AUTOSAR XML (schema 4-2-2)
package /STELLANTIS/EPT/ASWCs
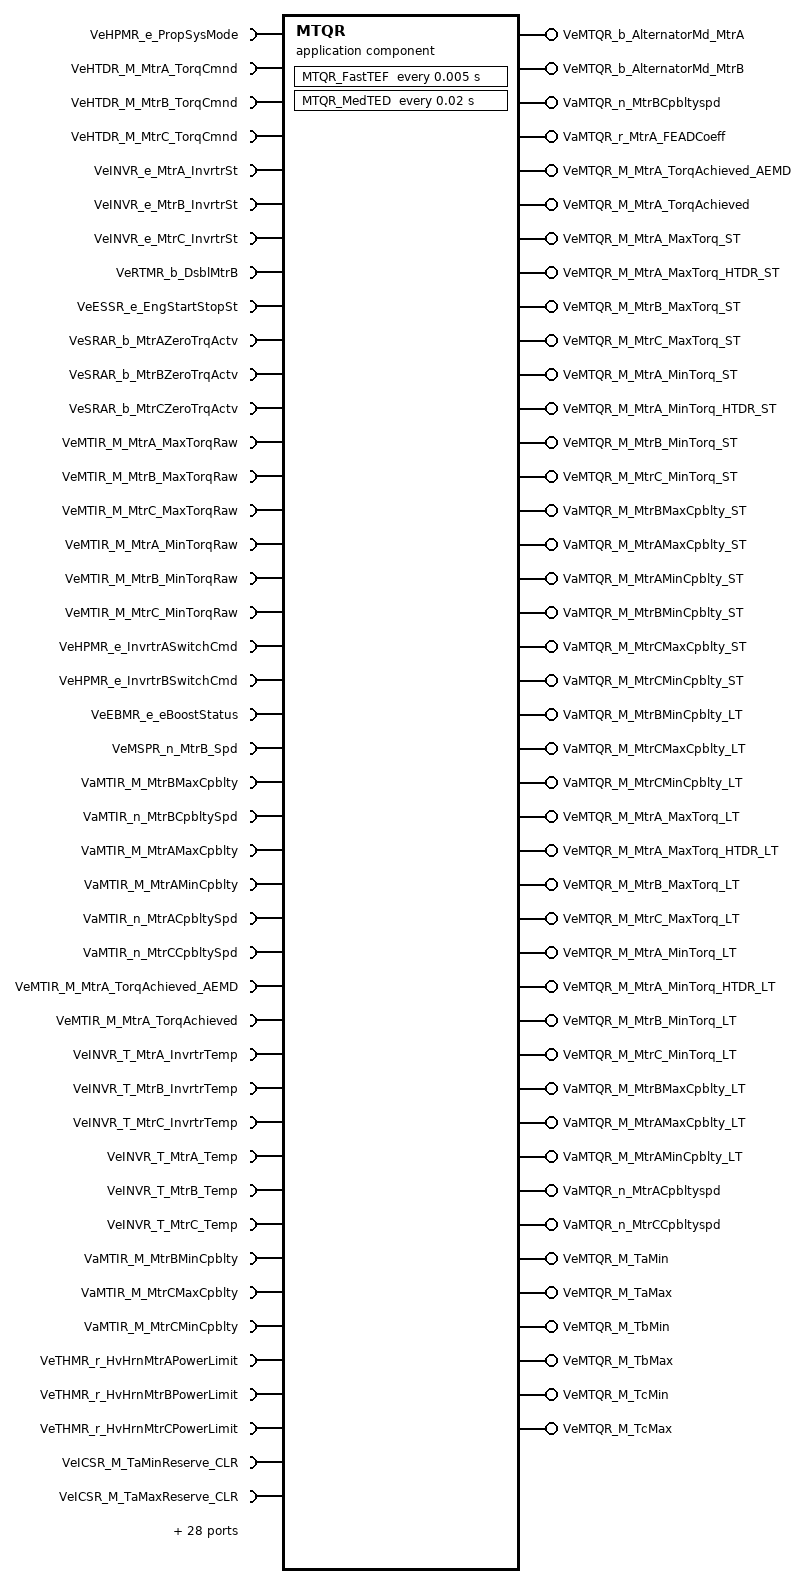
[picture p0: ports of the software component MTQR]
  application sw component type MTQR
    70 x require port:
      VeHPMR_e_PropSysMode: nonqueued-receiver-com-spec{data-element=Value, init-value=CeHPMR_e_Disabled}, required-interface=VeHPMR_e_PropSysMode
      VeHTDR_M_MtrA_TorqCmnd: nonqueued-receiver-com-spec{data-element=Value, init-value=0}, required-interface=VeHTDR_M_MtrA_TorqCmnd
      VeHTDR_M_MtrB_TorqCmnd: nonqueued-receiver-com-spec{data-element=Value, init-value=0}, required-interface=VeHTDR_M_MtrB_TorqCmnd
      VeHTDR_M_MtrC_TorqCmnd: nonqueued-receiver-com-spec{data-element=Value, init-value=0}, required-interface=VeHTDR_M_MtrC_TorqCmnd
      VeINVR_e_MtrA_InvrtrSt: nonqueued-receiver-com-spec{data-element=Value, init-value=CeINVR_e_NormalPowerStageOff}, required-interface=VeINVR_e_MtrA_InvrtrSt
      VeINVR_e_MtrB_InvrtrSt: nonqueued-receiver-com-spec{data-element=Value, init-value=CeINVR_e_NormalPowerStageOff}, required-interface=VeINVR_e_MtrB_InvrtrSt
      VeINVR_e_MtrC_InvrtrSt: nonqueued-receiver-com-spec{data-element=Value, init-value=CeINVR_e_NormalPowerStageOff}, required-interface=VeINVR_e_MtrC_InvrtrSt
      VeRTMR_b_DsblMtrB: nonqueued-receiver-com-spec{data-element=Value, init-value=0}, required-interface=VeRTMR_b_DsblMtrB
      VeESSR_e_EngStartStopSt: nonqueued-receiver-com-spec{data-element=Value, init-value=CeESSR_e_EngOff}, required-interface=VeESSR_e_EngStartStopSt
      VeSRAR_b_MtrAZeroTrqActv: nonqueued-receiver-com-spec{data-element=Value, init-value=0}, required-interface=VeSRAR_b_MtrAZeroTrqActv
      VeSRAR_b_MtrBZeroTrqActv: nonqueued-receiver-com-spec{data-element=Value, init-value=0}, required-interface=VeSRAR_b_MtrBZeroTrqActv
      VeSRAR_b_MtrCZeroTrqActv: nonqueued-receiver-com-spec{data-element=Value, init-value=0}, required-interface=VeSRAR_b_MtrCZeroTrqActv
      VeMTIR_M_MtrA_MaxTorqRaw: nonqueued-receiver-com-spec{data-element=Value, init-value=0}, required-interface=VeMTIR_M_MtrA_MaxTorqRaw
      VeMTIR_M_MtrB_MaxTorqRaw: nonqueued-receiver-com-spec{data-element=Value, init-value=0}, required-interface=VeMTIR_M_MtrB_MaxTorqRaw
      VeMTIR_M_MtrC_MaxTorqRaw: nonqueued-receiver-com-spec{data-element=Value, init-value=0}, required-interface=VeMTIR_M_MtrC_MaxTorqRaw
      VeMTIR_M_MtrA_MinTorqRaw: nonqueued-receiver-com-spec{data-element=Value, init-value=0}, required-interface=VeMTIR_M_MtrA_MinTorqRaw
      VeMTIR_M_MtrB_MinTorqRaw: nonqueued-receiver-com-spec{data-element=Value, init-value=0}, required-interface=VeMTIR_M_MtrB_MinTorqRaw
      VeMTIR_M_MtrC_MinTorqRaw: nonqueued-receiver-com-spec{data-element=Value, init-value=0}, required-interface=VeMTIR_M_MtrC_MinTorqRaw
      VeHPMR_e_InvrtrASwitchCmd: nonqueued-receiver-com-spec{data-element=Value, init-value=CeHPMR_e_Disable}, required-interface=VeHPMR_e_InvrtrASwitchCmd
      VeHPMR_e_InvrtrBSwitchCmd: nonqueued-receiver-com-spec{data-element=Value, init-value=CeHPMR_e_Disable}, required-interface=VeHPMR_e_InvrtrBSwitchCmd
      VeEBMR_e_eBoostStatus: nonqueued-receiver-com-spec{data-element=Value, init-value=CeEBMR_e_eBoostOFF}, required-interface=VeEBMR_e_eBoostStatus
      VeMSPR_n_MtrB_Spd: nonqueued-receiver-com-spec{data-element=Value, init-value=0}, required-interface=VeMSPR_n_MtrB_Spd
      VaMTIR_M_MtrBMaxCpblty: nonqueued-receiver-com-spec{data-element=Value, init-value=16 x 0}, required-interface=VaMTIR_M_MtrBMaxCpblty
      VaMTIR_n_MtrBCpbltySpd: nonqueued-receiver-com-spec{data-element=Value, init-value=16 x 0}, required-interface=VaMTIR_n_MtrBCpbltySpd
      VaMTIR_M_MtrAMaxCpblty: nonqueued-receiver-com-spec{data-element=Value, init-value=16 x 0}, required-interface=VaMTIR_M_MtrAMaxCpblty
      VaMTIR_M_MtrAMinCpblty: nonqueued-receiver-com-spec{data-element=Value, init-value=16 x 0}, required-interface=VaMTIR_M_MtrAMinCpblty
      VaMTIR_n_MtrACpbltySpd: nonqueued-receiver-com-spec{data-element=Value, init-value=16 x 0}, required-interface=VaMTIR_n_MtrACpbltySpd
      VaMTIR_n_MtrCCpbltySpd: nonqueued-receiver-com-spec{data-element=Value, init-value=16 x 0}, required-interface=VaMTIR_n_MtrCCpbltySpd
      VeMTIR_M_MtrA_TorqAchieved_AEMD: nonqueued-receiver-com-spec{data-element=Value, init-value=0}, required-interface=VeMTIR_M_MtrA_TorqAchieved_AEMD
      VeMTIR_M_MtrA_TorqAchieved: nonqueued-receiver-com-spec{data-element=Value, init-value=0}, required-interface=VeMTIR_M_MtrA_TorqAchieved
      VeINVR_T_MtrA_InvrtrTemp: nonqueued-receiver-com-spec{data-element=Value, init-value=0}, required-interface=VeINVR_T_MtrA_InvrtrTemp
      VeINVR_T_MtrB_InvrtrTemp: nonqueued-receiver-com-spec{data-element=Value, init-value=0}, required-interface=VeINVR_T_MtrB_InvrtrTemp
      VeINVR_T_MtrC_InvrtrTemp: nonqueued-receiver-com-spec{data-element=Value, init-value=0}, required-interface=VeINVR_T_MtrC_InvrtrTemp
      VeINVR_T_MtrA_Temp: nonqueued-receiver-com-spec{data-element=Value, init-value=0}, required-interface=VeINVR_T_MtrA_Temp
      VeINVR_T_MtrB_Temp: nonqueued-receiver-com-spec{data-element=Value, init-value=0}, required-interface=VeINVR_T_MtrB_Temp
      VeINVR_T_MtrC_Temp: nonqueued-receiver-com-spec{data-element=Value, init-value=0}, required-interface=VeINVR_T_MtrC_Temp
      VaMTIR_M_MtrBMinCpblty: nonqueued-receiver-com-spec{data-element=Value, init-value=16 x 0}, required-interface=VaMTIR_M_MtrBMinCpblty
      VaMTIR_M_MtrCMaxCpblty: nonqueued-receiver-com-spec{data-element=Value, init-value=16 x 0}, required-interface=VaMTIR_M_MtrCMaxCpblty
      VaMTIR_M_MtrCMinCpblty: nonqueued-receiver-com-spec{data-element=Value, init-value=16 x 0}, required-interface=VaMTIR_M_MtrCMinCpblty
      VeTHMR_r_HvHrnMtrAPowerLimit: nonqueued-receiver-com-spec{data-element=Value, init-value=0}, required-interface=VeTHMR_r_HvHrnMtrAPowerLimit
      VeTHMR_r_HvHrnMtrBPowerLimit: nonqueued-receiver-com-spec{data-element=Value, init-value=0}, required-interface=VeTHMR_r_HvHrnMtrBPowerLimit
      VeTHMR_r_HvHrnMtrCPowerLimit: nonqueued-receiver-com-spec{data-element=Value, init-value=0}, required-interface=VeTHMR_r_HvHrnMtrCPowerLimit
      VeICSR_M_TaMinReserve_CLR: nonqueued-receiver-com-spec{data-element=Value, init-value=0}, required-interface=VeICSR_M_TaMinReserve_CLR
      VeICSR_M_TaMaxReserve_CLR: nonqueued-receiver-com-spec{data-element=Value, init-value=0}, required-interface=VeICSR_M_TaMaxReserve_CLR
      VeICSR_M_TbMinReserve_CLR: nonqueued-receiver-com-spec{data-element=Value, init-value=0}, required-interface=VeICSR_M_TbMinReserve_CLR
      VeICSR_M_TbMaxReserve_CLR: nonqueued-receiver-com-spec{data-element=Value, init-value=0}, required-interface=VeICSR_M_TbMaxReserve_CLR
      VeHADR_M_MtrA_ReserveTorqNeg: nonqueued-receiver-com-spec{data-element=Value, init-value=0}, required-interface=VeHADR_M_MtrA_ReserveTorqNeg
      VeHADR_M_MtrA_ReserveTorqPos: nonqueued-receiver-com-spec{data-element=Value, init-value=0}, required-interface=VeHADR_M_MtrA_ReserveTorqPos
      VeHADR_M_MtrB_ReserveTorqNeg: nonqueued-receiver-com-spec{data-element=Value, init-value=0}, required-interface=VeHADR_M_MtrB_ReserveTorqNeg
      VeHADR_M_MtrB_ReserveTorqPos: nonqueued-receiver-com-spec{data-element=Value, init-value=0}, required-interface=VeHADR_M_MtrB_ReserveTorqPos
      VeESSR_M_MtrA_MinTorq: nonqueued-receiver-com-spec{data-element=Value, init-value=0}, required-interface=VeESSR_M_MtrA_MinTorq
      VeESSR_M_MtrA_MaxTorq: nonqueued-receiver-com-spec{data-element=Value, init-value=0}, required-interface=VeESSR_M_MtrA_MaxTorq
      VeESSR_M_MtrB_MinTorq: nonqueued-receiver-com-spec{data-element=Value, init-value=0}, required-interface=VeESSR_M_MtrB_MinTorq
      VeESSR_M_MtrB_MaxTorq: nonqueued-receiver-com-spec{data-element=Value, init-value=0}, required-interface=VeESSR_M_MtrB_MaxTorq
      VeHADR_M_MtrC_ReserveTorqNeg: nonqueued-receiver-com-spec{data-element=Value, init-value=0}, required-interface=VeHADR_M_MtrC_ReserveTorqNeg
      VeHADR_M_MtrC_ReserveTorqPos: nonqueued-receiver-com-spec{data-element=Value, init-value=0}, required-interface=VeHADR_M_MtrC_ReserveTorqPos
      VeESSR_M_MtrC_MinTorq: nonqueued-receiver-com-spec{data-element=Value, init-value=0}, required-interface=VeESSR_M_MtrC_MinTorq
      VeESSR_M_MtrC_MaxTorq: nonqueued-receiver-com-spec{data-element=Value, init-value=0}, required-interface=VeESSR_M_MtrC_MaxTorq
      VeHSER_b_DisablNxClsdLoopCntrl: nonqueued-receiver-com-spec{data-element=Value, init-value=0}, required-interface=VeHSER_b_DisablNxClsdLoopCntrl
      VeBCPR_M_BeltTrqMinHTDR: nonqueued-receiver-com-spec{data-element=Value, init-value=0}, required-interface=VeBCPR_M_BeltTrqMinHTDR
      VeBCPR_M_BeltTrqMaxHTDR: nonqueued-receiver-com-spec{data-element=Value, init-value=0}, required-interface=VeBCPR_M_BeltTrqMaxHTDR
      VeICSR_b_Disable_Ni_Global: nonqueued-receiver-com-spec{data-element=Value, init-value=0}, required-interface=VeICSR_b_Disable_Ni_Global
      VeESSR_b_AStrtPBatBoostReq: nonqueued-receiver-com-spec{data-element=Value, init-value=0}, required-interface=VeESSR_b_AStrtPBatBoostReq
      VeSCCR_b_FrntAxlRq: nonqueued-receiver-com-spec{data-element=Value, init-value=0}, required-interface=VeSCCR_b_FrntAxlRq
      VeSCCR_b_RrAxlRq: nonqueued-receiver-com-spec{data-element=Value, init-value=0}, required-interface=VeSCCR_b_RrAxlRq
      VeDTRR_e_AxleTrqRespType: nonqueued-receiver-com-spec{data-element=Value, init-value=CePTAR_e_Inactive}, required-interface=VeDTRR_e_AxleTrqRespType
      VeINVR_b_DMPI_TempStopFlag: nonqueued-receiver-com-spec{data-element=Value, init-value=0}, required-interface=VeINVR_b_DMPI_TempStopFlag
      VeRTMR_b_DsblMtr_OITR: nonqueued-receiver-com-spec{data-element=Value, init-value=0}, required-interface=VeRTMR_b_DsblMtr_OITR
      VeRTMR_b_DsblMtrA: nonqueued-receiver-com-spec{data-element=Value, init-value=0}, required-interface=VeRTMR_b_DsblMtrA
      VeESSR_b_DisableMtrA: nonqueued-receiver-com-spec{data-element=Value, init-value=0}, required-interface=VeESSR_b_DisableMtrA
    42 x provide port:
      VeMTQR_b_AlternatorMd_MtrA: nonqueued-sender-com-spec{data-element=Value, init-value=0}, provided-interface=VeMTQR_b_AlternatorMd_MtrA
      VeMTQR_b_AlternatorMd_MtrB: nonqueued-sender-com-spec{data-element=Value, init-value=0}, provided-interface=VeMTQR_b_AlternatorMd_MtrB
      VaMTQR_n_MtrBCpbltyspd: nonqueued-sender-com-spec{data-element=Value, init-value=16 x 0}, provided-interface=VaMTQR_n_MtrBCpbltyspd
      VaMTQR_r_MtrA_FEADCoeff: nonqueued-sender-com-spec{data-element=Value, init-value=[0, 0, 0]}, provided-interface=VaMTQR_r_MtrA_FEADCoeff
      VeMTQR_M_MtrA_TorqAchieved_AEMD: nonqueued-sender-com-spec{data-element=Value, init-value=0}, provided-interface=VeMTQR_M_MtrA_TorqAchieved_AEMD
      VeMTQR_M_MtrA_TorqAchieved: nonqueued-sender-com-spec{data-element=Value, init-value=0}, provided-interface=VeMTQR_M_MtrA_TorqAchieved
      VeMTQR_M_MtrA_MaxTorq_ST: nonqueued-sender-com-spec{data-element=Value, init-value=0}, provided-interface=VeMTQR_M_MtrA_MaxTorq_ST
      VeMTQR_M_MtrA_MaxTorq_HTDR_ST: nonqueued-sender-com-spec{data-element=Value, init-value=0}, provided-interface=VeMTQR_M_MtrA_MaxTorq_HTDR_ST
      VeMTQR_M_MtrB_MaxTorq_ST: nonqueued-sender-com-spec{data-element=Value, init-value=0}, provided-interface=VeMTQR_M_MtrB_MaxTorq_ST
      VeMTQR_M_MtrC_MaxTorq_ST: nonqueued-sender-com-spec{data-element=Value, init-value=0}, provided-interface=VeMTQR_M_MtrC_MaxTorq_ST
      VeMTQR_M_MtrA_MinTorq_ST: nonqueued-sender-com-spec{data-element=Value, init-value=0}, provided-interface=VeMTQR_M_MtrA_MinTorq_ST
      VeMTQR_M_MtrA_MinTorq_HTDR_ST: nonqueued-sender-com-spec{data-element=Value, init-value=0}, provided-interface=VeMTQR_M_MtrA_MinTorq_HTDR_ST
      VeMTQR_M_MtrB_MinTorq_ST: nonqueued-sender-com-spec{data-element=Value, init-value=0}, provided-interface=VeMTQR_M_MtrB_MinTorq_ST
      VeMTQR_M_MtrC_MinTorq_ST: nonqueued-sender-com-spec{data-element=Value, init-value=0}, provided-interface=VeMTQR_M_MtrC_MinTorq_ST
      VaMTQR_M_MtrBMaxCpblty_ST: nonqueued-sender-com-spec{data-element=Value, init-value=16 x 0}, provided-interface=VaMTQR_M_MtrBMaxCpblty_ST
      VaMTQR_M_MtrAMaxCpblty_ST: nonqueued-sender-com-spec{data-element=Value, init-value=16 x 0}, provided-interface=VaMTQR_M_MtrAMaxCpblty_ST
      VaMTQR_M_MtrAMinCpblty_ST: nonqueued-sender-com-spec{data-element=Value, init-value=16 x 0}, provided-interface=VaMTQR_M_MtrAMinCpblty_ST
      VaMTQR_M_MtrBMinCpblty_ST: nonqueued-sender-com-spec{data-element=Value, init-value=16 x 0}, provided-interface=VaMTQR_M_MtrBMinCpblty_ST
      VaMTQR_M_MtrCMaxCpblty_ST: nonqueued-sender-com-spec{data-element=Value, init-value=16 x 0}, provided-interface=VaMTQR_M_MtrCMaxCpblty_ST
      VaMTQR_M_MtrCMinCpblty_ST: nonqueued-sender-com-spec{data-element=Value, init-value=16 x 0}, provided-interface=VaMTQR_M_MtrCMinCpblty_ST
      VaMTQR_M_MtrBMinCpblty_LT: nonqueued-sender-com-spec{data-element=Value, init-value=16 x 0}, provided-interface=VaMTQR_M_MtrBMinCpblty_LT
      VaMTQR_M_MtrCMaxCpblty_LT: nonqueued-sender-com-spec{data-element=Value, init-value=16 x 0}, provided-interface=VaMTQR_M_MtrCMaxCpblty_LT
      VaMTQR_M_MtrCMinCpblty_LT: nonqueued-sender-com-spec{data-element=Value, init-value=16 x 0}, provided-interface=VaMTQR_M_MtrCMinCpblty_LT
      VeMTQR_M_MtrA_MaxTorq_LT: nonqueued-sender-com-spec{data-element=Value, init-value=0}, provided-interface=VeMTQR_M_MtrA_MaxTorq_LT
      VeMTQR_M_MtrA_MaxTorq_HTDR_LT: nonqueued-sender-com-spec{data-element=Value, init-value=0}, provided-interface=VeMTQR_M_MtrA_MaxTorq_HTDR_LT
      VeMTQR_M_MtrB_MaxTorq_LT: nonqueued-sender-com-spec{data-element=Value, init-value=0}, provided-interface=VeMTQR_M_MtrB_MaxTorq_LT
      VeMTQR_M_MtrC_MaxTorq_LT: nonqueued-sender-com-spec{data-element=Value, init-value=0}, provided-interface=VeMTQR_M_MtrC_MaxTorq_LT
      VeMTQR_M_MtrA_MinTorq_LT: nonqueued-sender-com-spec{data-element=Value, init-value=0}, provided-interface=VeMTQR_M_MtrA_MinTorq_LT
      VeMTQR_M_MtrA_MinTorq_HTDR_LT: nonqueued-sender-com-spec{data-element=Value, init-value=0}, provided-interface=VeMTQR_M_MtrA_MinTorq_HTDR_LT
      VeMTQR_M_MtrB_MinTorq_LT: nonqueued-sender-com-spec{data-element=Value, init-value=0}, provided-interface=VeMTQR_M_MtrB_MinTorq_LT
      VeMTQR_M_MtrC_MinTorq_LT: nonqueued-sender-com-spec{data-element=Value, init-value=0}, provided-interface=VeMTQR_M_MtrC_MinTorq_LT
      VaMTQR_M_MtrBMaxCpblty_LT: nonqueued-sender-com-spec{data-element=Value, init-value=16 x 0}, provided-interface=VaMTQR_M_MtrBMaxCpblty_LT
      VaMTQR_M_MtrAMaxCpblty_LT: nonqueued-sender-com-spec{data-element=Value, init-value=16 x 0}, provided-interface=VaMTQR_M_MtrAMaxCpblty_LT
      VaMTQR_M_MtrAMinCpblty_LT: nonqueued-sender-com-spec{data-element=Value, init-value=16 x 0}, provided-interface=VaMTQR_M_MtrAMinCpblty_LT
      VaMTQR_n_MtrACpbltyspd: nonqueued-sender-com-spec{data-element=Value, init-value=16 x 0}, provided-interface=VaMTQR_n_MtrACpbltyspd
      VaMTQR_n_MtrCCpbltyspd: nonqueued-sender-com-spec{data-element=Value, init-value=16 x 0}, provided-interface=VaMTQR_n_MtrCCpbltyspd
      VeMTQR_M_TaMin: nonqueued-sender-com-spec{data-element=Value, init-value=0}, provided-interface=VeMTQR_M_TaMin
      VeMTQR_M_TaMax: nonqueued-sender-com-spec{data-element=Value, init-value=0}, provided-interface=VeMTQR_M_TaMax
      VeMTQR_M_TbMin: nonqueued-sender-com-spec{data-element=Value, init-value=0}, provided-interface=VeMTQR_M_TbMin
      VeMTQR_M_TbMax: nonqueued-sender-com-spec{data-element=Value, init-value=0}, provided-interface=VeMTQR_M_TbMax
      VeMTQR_M_TcMin: nonqueued-sender-com-spec{data-element=Value, init-value=0}, provided-interface=VeMTQR_M_TcMin
      VeMTQR_M_TcMax: nonqueued-sender-com-spec{data-element=Value, init-value=0}, provided-interface=VeMTQR_M_TcMax
    require port KeTSXR_r_P1f: parameter-require-com-spec{init-value=KeTSXR_r_P1f_KeTSXR_r_P1f:2.55550003051758, parameter=KeTSXR_r_P1f}, required-interface=KeTSXR_r_P1f
    require port KeHSCR_b_FEADadj: parameter-require-com-spec{init-value=KeHSCR_b_FEADadj_KeHSCR_b_FEADadj:0, parameter=KeHSCR_b_FEADadj}, required-interface=KeHSCR_b_FEADadj
    behavior IB_MTQR: data-type-mapping=msADTtoIDTMapping, handle-termination-and-restart=NO-SUPPORT
      timing event Event_FastTEF: start-on-event=MTQR_FastTEF, period=0.005
      timing event Event_MedTED: start-on-event=MTQR_MedTED, period=0.02
      init event Event_MTQR_ac_Init: start-on-event=MTQR_ac_Init
      init event Event_PwrOn: start-on-event=MTQR_PwrOn
      explicit-inter-runnable-variables:
        data FEAD_Elements_write_IRV: category=ARRAY, sw-calibration-access=READ-ONLY, type=rt_Array_Float_3, init-value=[0, 0, 0]
      4 x runnable:
        MTQR_ac_Init
          data-send-points:
            16 x access:
              OUT_VaMTQR_n_MtrBCpbltyspd_Value: accessed-variable=VaMTQR_n_MtrBCpbltyspd.Value
              OUT_VaMTQR_r_MtrA_FEADCoeff_Value: accessed-variable=VaMTQR_r_MtrA_FEADCoeff.Value
              OUT_VaMTQR_M_MtrBMaxCpblty_ST_Value: accessed-variable=VaMTQR_M_MtrBMaxCpblty_ST.Value
              OUT_VaMTQR_M_MtrAMaxCpblty_ST_Value: accessed-variable=VaMTQR_M_MtrAMaxCpblty_ST.Value
              OUT_VaMTQR_M_MtrAMinCpblty_ST_Value: accessed-variable=VaMTQR_M_MtrAMinCpblty_ST.Value
              OUT_VaMTQR_M_MtrBMinCpblty_ST_Value: accessed-variable=VaMTQR_M_MtrBMinCpblty_ST.Value
              OUT_VaMTQR_M_MtrCMaxCpblty_ST_Value: accessed-variable=VaMTQR_M_MtrCMaxCpblty_ST.Value
              OUT_VaMTQR_M_MtrCMinCpblty_ST_Value: accessed-variable=VaMTQR_M_MtrCMinCpblty_ST.Value
              OUT_VaMTQR_M_MtrBMinCpblty_LT_Value: accessed-variable=VaMTQR_M_MtrBMinCpblty_LT.Value
              OUT_VaMTQR_M_MtrCMaxCpblty_LT_Value: accessed-variable=VaMTQR_M_MtrCMaxCpblty_LT.Value
              OUT_VaMTQR_M_MtrCMinCpblty_LT_Value: accessed-variable=VaMTQR_M_MtrCMinCpblty_LT.Value
              OUT_VaMTQR_M_MtrBMaxCpblty_LT_Value: accessed-variable=VaMTQR_M_MtrBMaxCpblty_LT.Value
              OUT_VaMTQR_M_MtrAMaxCpblty_LT_Value: accessed-variable=VaMTQR_M_MtrAMaxCpblty_LT.Value
              OUT_VaMTQR_M_MtrAMinCpblty_LT_Value: accessed-variable=VaMTQR_M_MtrAMinCpblty_LT.Value
              OUT_VaMTQR_n_MtrACpbltyspd_Value: accessed-variable=VaMTQR_n_MtrACpbltyspd.Value
              OUT_VaMTQR_n_MtrCCpbltyspd_Value: accessed-variable=VaMTQR_n_MtrCCpbltyspd.Value
          written-local-variables:
            access WV_FEAD_Elements_write_IRV: accessed-variable=FEAD_Elements_write_IRV
        MTQR_FastTEF
          data-receive-point-by-arguments:
            70 x access:
              IN_VaMTIR_M_MtrAMaxCpblty_Value: accessed-variable=VaMTIR_M_MtrAMaxCpblty.Value
              IN_VaMTIR_M_MtrAMinCpblty_Value: accessed-variable=VaMTIR_M_MtrAMinCpblty.Value
              IN_VaMTIR_M_MtrBMaxCpblty_Value: accessed-variable=VaMTIR_M_MtrBMaxCpblty.Value
              IN_VaMTIR_M_MtrBMinCpblty_Value: accessed-variable=VaMTIR_M_MtrBMinCpblty.Value
              IN_VaMTIR_M_MtrCMaxCpblty_Value: accessed-variable=VaMTIR_M_MtrCMaxCpblty.Value
              IN_VaMTIR_M_MtrCMinCpblty_Value: accessed-variable=VaMTIR_M_MtrCMinCpblty.Value
              IN_VaMTIR_n_MtrACpbltySpd_Value: accessed-variable=VaMTIR_n_MtrACpbltySpd.Value
              IN_VaMTIR_n_MtrBCpbltySpd_Value: accessed-variable=VaMTIR_n_MtrBCpbltySpd.Value
              IN_VaMTIR_n_MtrCCpbltySpd_Value: accessed-variable=VaMTIR_n_MtrCCpbltySpd.Value
              IN_VeBCPR_M_BeltTrqMaxHTDR_Value: accessed-variable=VeBCPR_M_BeltTrqMaxHTDR.Value
              IN_VeBCPR_M_BeltTrqMinHTDR_Value: accessed-variable=VeBCPR_M_BeltTrqMinHTDR.Value
              IN_VeDTRR_e_AxleTrqRespType_Value: accessed-variable=VeDTRR_e_AxleTrqRespType.Value
              IN_VeEBMR_e_eBoostStatus_Value: accessed-variable=VeEBMR_e_eBoostStatus.Value
              IN_VeESSR_M_MtrA_MaxTorq_Value: accessed-variable=VeESSR_M_MtrA_MaxTorq.Value
              IN_VeESSR_M_MtrA_MinTorq_Value: accessed-variable=VeESSR_M_MtrA_MinTorq.Value
              IN_VeESSR_M_MtrB_MaxTorq_Value: accessed-variable=VeESSR_M_MtrB_MaxTorq.Value
              IN_VeESSR_M_MtrB_MinTorq_Value: accessed-variable=VeESSR_M_MtrB_MinTorq.Value
              IN_VeESSR_M_MtrC_MaxTorq_Value: accessed-variable=VeESSR_M_MtrC_MaxTorq.Value
              IN_VeESSR_M_MtrC_MinTorq_Value: accessed-variable=VeESSR_M_MtrC_MinTorq.Value
              IN_VeESSR_b_AStrtPBatBoostReq_Value: accessed-variable=VeESSR_b_AStrtPBatBoostReq.Value
              IN_VeESSR_b_DisableMtrA_Value: accessed-variable=VeESSR_b_DisableMtrA.Value
              IN_VeESSR_e_EngStartStopSt_Value: accessed-variable=VeESSR_e_EngStartStopSt.Value
              IN_VeHADR_M_MtrA_ReserveTorqNeg_Value: accessed-variable=VeHADR_M_MtrA_ReserveTorqNeg.Value
              IN_VeHADR_M_MtrA_ReserveTorqPos_Value: accessed-variable=VeHADR_M_MtrA_ReserveTorqPos.Value
              IN_VeHADR_M_MtrB_ReserveTorqNeg_Value: accessed-variable=VeHADR_M_MtrB_ReserveTorqNeg.Value
              IN_VeHADR_M_MtrB_ReserveTorqPos_Value: accessed-variable=VeHADR_M_MtrB_ReserveTorqPos.Value
              IN_VeHADR_M_MtrC_ReserveTorqNeg_Value: accessed-variable=VeHADR_M_MtrC_ReserveTorqNeg.Value
              IN_VeHADR_M_MtrC_ReserveTorqPos_Value: accessed-variable=VeHADR_M_MtrC_ReserveTorqPos.Value
              IN_VeHPMR_e_InvrtrASwitchCmd_Value: accessed-variable=VeHPMR_e_InvrtrASwitchCmd.Value
              IN_VeHPMR_e_InvrtrBSwitchCmd_Value: accessed-variable=VeHPMR_e_InvrtrBSwitchCmd.Value
              IN_VeHPMR_e_PropSysMode_Value: accessed-variable=VeHPMR_e_PropSysMode.Value
              IN_VeHSER_b_DisablNxClsdLoopCntrl_Value: accessed-variable=VeHSER_b_DisablNxClsdLoopCntrl.Value
              IN_VeHTDR_M_MtrA_TorqCmnd_Value: accessed-variable=VeHTDR_M_MtrA_TorqCmnd.Value
              IN_VeHTDR_M_MtrB_TorqCmnd_Value: accessed-variable=VeHTDR_M_MtrB_TorqCmnd.Value
              IN_VeHTDR_M_MtrC_TorqCmnd_Value: accessed-variable=VeHTDR_M_MtrC_TorqCmnd.Value
              IN_VeICSR_M_TaMaxReserve_CLR_Value: accessed-variable=VeICSR_M_TaMaxReserve_CLR.Value
              IN_VeICSR_M_TaMinReserve_CLR_Value: accessed-variable=VeICSR_M_TaMinReserve_CLR.Value
              IN_VeICSR_M_TbMaxReserve_CLR_Value: accessed-variable=VeICSR_M_TbMaxReserve_CLR.Value
              IN_VeICSR_M_TbMinReserve_CLR_Value: accessed-variable=VeICSR_M_TbMinReserve_CLR.Value
              IN_VeICSR_b_Disable_Ni_Global_Value: accessed-variable=VeICSR_b_Disable_Ni_Global.Value
              IN_VeINVR_T_MtrA_InvrtrTemp_Value: accessed-variable=VeINVR_T_MtrA_InvrtrTemp.Value
              IN_VeINVR_T_MtrA_Temp_Value: accessed-variable=VeINVR_T_MtrA_Temp.Value
              IN_VeINVR_T_MtrB_InvrtrTemp_Value: accessed-variable=VeINVR_T_MtrB_InvrtrTemp.Value
              IN_VeINVR_T_MtrB_Temp_Value: accessed-variable=VeINVR_T_MtrB_Temp.Value
              IN_VeINVR_T_MtrC_InvrtrTemp_Value: accessed-variable=VeINVR_T_MtrC_InvrtrTemp.Value
              IN_VeINVR_T_MtrC_Temp_Value: accessed-variable=VeINVR_T_MtrC_Temp.Value
              IN_VeINVR_b_DMPI_TempStopFlag_Value: accessed-variable=VeINVR_b_DMPI_TempStopFlag.Value
              IN_VeINVR_e_MtrA_InvrtrSt_Value: accessed-variable=VeINVR_e_MtrA_InvrtrSt.Value
              IN_VeINVR_e_MtrB_InvrtrSt_Value: accessed-variable=VeINVR_e_MtrB_InvrtrSt.Value
              IN_VeINVR_e_MtrC_InvrtrSt_Value: accessed-variable=VeINVR_e_MtrC_InvrtrSt.Value
              IN_VeMSPR_n_MtrB_Spd_Value: accessed-variable=VeMSPR_n_MtrB_Spd.Value
              IN_VeMTIR_M_MtrA_MaxTorqRaw_Value: accessed-variable=VeMTIR_M_MtrA_MaxTorqRaw.Value
              IN_VeMTIR_M_MtrA_MinTorqRaw_Value: accessed-variable=VeMTIR_M_MtrA_MinTorqRaw.Value
              IN_VeMTIR_M_MtrA_TorqAchieved_Value: accessed-variable=VeMTIR_M_MtrA_TorqAchieved.Value
              IN_VeMTIR_M_MtrA_TorqAchieved_AEMD_Value: accessed-variable=VeMTIR_M_MtrA_TorqAchieved_AEMD.Value
              IN_VeMTIR_M_MtrB_MaxTorqRaw_Value: accessed-variable=VeMTIR_M_MtrB_MaxTorqRaw.Value
              IN_VeMTIR_M_MtrB_MinTorqRaw_Value: accessed-variable=VeMTIR_M_MtrB_MinTorqRaw.Value
              IN_VeMTIR_M_MtrC_MaxTorqRaw_Value: accessed-variable=VeMTIR_M_MtrC_MaxTorqRaw.Value
              IN_VeMTIR_M_MtrC_MinTorqRaw_Value: accessed-variable=VeMTIR_M_MtrC_MinTorqRaw.Value
              IN_VeRTMR_b_DsblMtrA_Value: accessed-variable=VeRTMR_b_DsblMtrA.Value
              IN_VeRTMR_b_DsblMtrB_Value: accessed-variable=VeRTMR_b_DsblMtrB.Value
              IN_VeRTMR_b_DsblMtr_OITR_Value: accessed-variable=VeRTMR_b_DsblMtr_OITR.Value
              IN_VeSCCR_b_FrntAxlRq_Value: accessed-variable=VeSCCR_b_FrntAxlRq.Value
              IN_VeSCCR_b_RrAxlRq_Value: accessed-variable=VeSCCR_b_RrAxlRq.Value
              IN_VeSRAR_b_MtrAZeroTrqActv_Value: accessed-variable=VeSRAR_b_MtrAZeroTrqActv.Value
              IN_VeSRAR_b_MtrBZeroTrqActv_Value: accessed-variable=VeSRAR_b_MtrBZeroTrqActv.Value
              IN_VeSRAR_b_MtrCZeroTrqActv_Value: accessed-variable=VeSRAR_b_MtrCZeroTrqActv.Value
              IN_VeTHMR_r_HvHrnMtrAPowerLimit_Value: accessed-variable=VeTHMR_r_HvHrnMtrAPowerLimit.Value
              IN_VeTHMR_r_HvHrnMtrBPowerLimit_Value: accessed-variable=VeTHMR_r_HvHrnMtrBPowerLimit.Value
              IN_VeTHMR_r_HvHrnMtrCPowerLimit_Value: accessed-variable=VeTHMR_r_HvHrnMtrCPowerLimit.Value
          data-send-points:
            41 x access:
              OUT_VeMTQR_b_AlternatorMd_MtrA_Value: accessed-variable=VeMTQR_b_AlternatorMd_MtrA.Value
              OUT_VeMTQR_b_AlternatorMd_MtrB_Value: accessed-variable=VeMTQR_b_AlternatorMd_MtrB.Value
              OUT_VaMTQR_n_MtrBCpbltyspd_Value: accessed-variable=VaMTQR_n_MtrBCpbltyspd.Value
              OUT_VeMTQR_M_MtrA_TorqAchieved_AEMD_Value: accessed-variable=VeMTQR_M_MtrA_TorqAchieved_AEMD.Value
              OUT_VeMTQR_M_MtrA_TorqAchieved_Value: accessed-variable=VeMTQR_M_MtrA_TorqAchieved.Value
              OUT_VeMTQR_M_MtrA_MaxTorq_ST_Value: accessed-variable=VeMTQR_M_MtrA_MaxTorq_ST.Value
              OUT_VeMTQR_M_MtrA_MaxTorq_HTDR_ST_Value: accessed-variable=VeMTQR_M_MtrA_MaxTorq_HTDR_ST.Value
              OUT_VeMTQR_M_MtrB_MaxTorq_ST_Value: accessed-variable=VeMTQR_M_MtrB_MaxTorq_ST.Value
              OUT_VeMTQR_M_MtrC_MaxTorq_ST_Value: accessed-variable=VeMTQR_M_MtrC_MaxTorq_ST.Value
              OUT_VeMTQR_M_MtrA_MinTorq_ST_Value: accessed-variable=VeMTQR_M_MtrA_MinTorq_ST.Value
              OUT_VeMTQR_M_MtrA_MinTorq_HTDR_ST_Value: accessed-variable=VeMTQR_M_MtrA_MinTorq_HTDR_ST.Value
              OUT_VeMTQR_M_MtrB_MinTorq_ST_Value: accessed-variable=VeMTQR_M_MtrB_MinTorq_ST.Value
              OUT_VeMTQR_M_MtrC_MinTorq_ST_Value: accessed-variable=VeMTQR_M_MtrC_MinTorq_ST.Value
              OUT_VaMTQR_M_MtrBMaxCpblty_ST_Value: accessed-variable=VaMTQR_M_MtrBMaxCpblty_ST.Value
              OUT_VaMTQR_M_MtrAMaxCpblty_ST_Value: accessed-variable=VaMTQR_M_MtrAMaxCpblty_ST.Value
              OUT_VaMTQR_M_MtrAMinCpblty_ST_Value: accessed-variable=VaMTQR_M_MtrAMinCpblty_ST.Value
              OUT_VaMTQR_M_MtrBMinCpblty_ST_Value: accessed-variable=VaMTQR_M_MtrBMinCpblty_ST.Value
              OUT_VaMTQR_M_MtrCMaxCpblty_ST_Value: accessed-variable=VaMTQR_M_MtrCMaxCpblty_ST.Value
              OUT_VaMTQR_M_MtrCMinCpblty_ST_Value: accessed-variable=VaMTQR_M_MtrCMinCpblty_ST.Value
              OUT_VaMTQR_M_MtrBMinCpblty_LT_Value: accessed-variable=VaMTQR_M_MtrBMinCpblty_LT.Value
              OUT_VaMTQR_M_MtrCMaxCpblty_LT_Value: accessed-variable=VaMTQR_M_MtrCMaxCpblty_LT.Value
              OUT_VaMTQR_M_MtrCMinCpblty_LT_Value: accessed-variable=VaMTQR_M_MtrCMinCpblty_LT.Value
              OUT_VeMTQR_M_MtrA_MaxTorq_LT_Value: accessed-variable=VeMTQR_M_MtrA_MaxTorq_LT.Value
              OUT_VeMTQR_M_MtrA_MaxTorq_HTDR_LT_Value: accessed-variable=VeMTQR_M_MtrA_MaxTorq_HTDR_LT.Value
              OUT_VeMTQR_M_MtrB_MaxTorq_LT_Value: accessed-variable=VeMTQR_M_MtrB_MaxTorq_LT.Value
              OUT_VeMTQR_M_MtrC_MaxTorq_LT_Value: accessed-variable=VeMTQR_M_MtrC_MaxTorq_LT.Value
              OUT_VeMTQR_M_MtrA_MinTorq_LT_Value: accessed-variable=VeMTQR_M_MtrA_MinTorq_LT.Value
              OUT_VeMTQR_M_MtrA_MinTorq_HTDR_LT_Value: accessed-variable=VeMTQR_M_MtrA_MinTorq_HTDR_LT.Value
              OUT_VeMTQR_M_MtrB_MinTorq_LT_Value: accessed-variable=VeMTQR_M_MtrB_MinTorq_LT.Value
              OUT_VeMTQR_M_MtrC_MinTorq_LT_Value: accessed-variable=VeMTQR_M_MtrC_MinTorq_LT.Value
              OUT_VaMTQR_M_MtrBMaxCpblty_LT_Value: accessed-variable=VaMTQR_M_MtrBMaxCpblty_LT.Value
              OUT_VaMTQR_M_MtrAMaxCpblty_LT_Value: accessed-variable=VaMTQR_M_MtrAMaxCpblty_LT.Value
              OUT_VaMTQR_M_MtrAMinCpblty_LT_Value: accessed-variable=VaMTQR_M_MtrAMinCpblty_LT.Value
              OUT_VaMTQR_n_MtrACpbltyspd_Value: accessed-variable=VaMTQR_n_MtrACpbltyspd.Value
              OUT_VaMTQR_n_MtrCCpbltyspd_Value: accessed-variable=VaMTQR_n_MtrCCpbltyspd.Value
              OUT_VeMTQR_M_TaMin_Value: accessed-variable=VeMTQR_M_TaMin.Value
              OUT_VeMTQR_M_TaMax_Value: accessed-variable=VeMTQR_M_TaMax.Value
              OUT_VeMTQR_M_TbMin_Value: accessed-variable=VeMTQR_M_TbMin.Value
              OUT_VeMTQR_M_TbMax_Value: accessed-variable=VeMTQR_M_TbMax.Value
              OUT_VeMTQR_M_TcMin_Value: accessed-variable=VeMTQR_M_TcMin.Value
              OUT_VeMTQR_M_TcMax_Value: accessed-variable=VeMTQR_M_TcMax.Value
          parameter access CALPRM_KeHSCR_b_FEADadj_KeHSCR_b_FEADadj: accessed-parameter=KeHSCR_b_FEADadj.KeHSCR_b_FEADadj
          parameter access CALPRM_KeTSXR_r_P1f_KeTSXR_r_P1f: accessed-parameter=KeTSXR_r_P1f.KeTSXR_r_P1f
          read-local-variables:
            access RV_FEAD_Elements_write_IRV: accessed-variable=FEAD_Elements_write_IRV
        MTQR_MedTED
          data-send-points:
            access OUT_VaMTQR_r_MtrA_FEADCoeff_Value: accessed-variable=VaMTQR_r_MtrA_FEADCoeff.Value
          parameter access CALPRM_KeHSCR_b_FEADadj_KeHSCR_b_FEADadj: accessed-parameter=KeHSCR_b_FEADadj.KeHSCR_b_FEADadj
          written-local-variables:
            access WV_FEAD_Elements_write_IRV: accessed-variable=FEAD_Elements_write_IRV
        MTQR_PwrOn
          data-send-points:
            42 x access:
              OUT_VeMTQR_b_AlternatorMd_MtrA_Value: accessed-variable=VeMTQR_b_AlternatorMd_MtrA.Value
              OUT_VeMTQR_b_AlternatorMd_MtrB_Value: accessed-variable=VeMTQR_b_AlternatorMd_MtrB.Value
              OUT_VaMTQR_n_MtrBCpbltyspd_Value: accessed-variable=VaMTQR_n_MtrBCpbltyspd.Value
              OUT_VaMTQR_r_MtrA_FEADCoeff_Value: accessed-variable=VaMTQR_r_MtrA_FEADCoeff.Value
              OUT_VeMTQR_M_MtrA_TorqAchieved_AEMD_Value: accessed-variable=VeMTQR_M_MtrA_TorqAchieved_AEMD.Value
              OUT_VeMTQR_M_MtrA_TorqAchieved_Value: accessed-variable=VeMTQR_M_MtrA_TorqAchieved.Value
              OUT_VeMTQR_M_MtrA_MaxTorq_ST_Value: accessed-variable=VeMTQR_M_MtrA_MaxTorq_ST.Value
              OUT_VeMTQR_M_MtrA_MaxTorq_HTDR_ST_Value: accessed-variable=VeMTQR_M_MtrA_MaxTorq_HTDR_ST.Value
              OUT_VeMTQR_M_MtrB_MaxTorq_ST_Value: accessed-variable=VeMTQR_M_MtrB_MaxTorq_ST.Value
              OUT_VeMTQR_M_MtrC_MaxTorq_ST_Value: accessed-variable=VeMTQR_M_MtrC_MaxTorq_ST.Value
              OUT_VeMTQR_M_MtrA_MinTorq_ST_Value: accessed-variable=VeMTQR_M_MtrA_MinTorq_ST.Value
              OUT_VeMTQR_M_MtrA_MinTorq_HTDR_ST_Value: accessed-variable=VeMTQR_M_MtrA_MinTorq_HTDR_ST.Value
              OUT_VeMTQR_M_MtrB_MinTorq_ST_Value: accessed-variable=VeMTQR_M_MtrB_MinTorq_ST.Value
              OUT_VeMTQR_M_MtrC_MinTorq_ST_Value: accessed-variable=VeMTQR_M_MtrC_MinTorq_ST.Value
              OUT_VaMTQR_M_MtrBMaxCpblty_ST_Value: accessed-variable=VaMTQR_M_MtrBMaxCpblty_ST.Value
              OUT_VaMTQR_M_MtrAMaxCpblty_ST_Value: accessed-variable=VaMTQR_M_MtrAMaxCpblty_ST.Value
              OUT_VaMTQR_M_MtrAMinCpblty_ST_Value: accessed-variable=VaMTQR_M_MtrAMinCpblty_ST.Value
              OUT_VaMTQR_M_MtrBMinCpblty_ST_Value: accessed-variable=VaMTQR_M_MtrBMinCpblty_ST.Value
              OUT_VaMTQR_M_MtrCMaxCpblty_ST_Value: accessed-variable=VaMTQR_M_MtrCMaxCpblty_ST.Value
              OUT_VaMTQR_M_MtrCMinCpblty_ST_Value: accessed-variable=VaMTQR_M_MtrCMinCpblty_ST.Value
              OUT_VaMTQR_M_MtrBMinCpblty_LT_Value: accessed-variable=VaMTQR_M_MtrBMinCpblty_LT.Value
              OUT_VaMTQR_M_MtrCMaxCpblty_LT_Value: accessed-variable=VaMTQR_M_MtrCMaxCpblty_LT.Value
              OUT_VaMTQR_M_MtrCMinCpblty_LT_Value: accessed-variable=VaMTQR_M_MtrCMinCpblty_LT.Value
              OUT_VeMTQR_M_MtrA_MaxTorq_LT_Value: accessed-variable=VeMTQR_M_MtrA_MaxTorq_LT.Value
              OUT_VeMTQR_M_MtrA_MaxTorq_HTDR_LT_Value: accessed-variable=VeMTQR_M_MtrA_MaxTorq_HTDR_LT.Value
              OUT_VeMTQR_M_MtrB_MaxTorq_LT_Value: accessed-variable=VeMTQR_M_MtrB_MaxTorq_LT.Value
              OUT_VeMTQR_M_MtrC_MaxTorq_LT_Value: accessed-variable=VeMTQR_M_MtrC_MaxTorq_LT.Value
              OUT_VeMTQR_M_MtrA_MinTorq_LT_Value: accessed-variable=VeMTQR_M_MtrA_MinTorq_LT.Value
              OUT_VeMTQR_M_MtrA_MinTorq_HTDR_LT_Value: accessed-variable=VeMTQR_M_MtrA_MinTorq_HTDR_LT.Value
              OUT_VeMTQR_M_MtrB_MinTorq_LT_Value: accessed-variable=VeMTQR_M_MtrB_MinTorq_LT.Value
              OUT_VeMTQR_M_MtrC_MinTorq_LT_Value: accessed-variable=VeMTQR_M_MtrC_MinTorq_LT.Value
              OUT_VaMTQR_M_MtrBMaxCpblty_LT_Value: accessed-variable=VaMTQR_M_MtrBMaxCpblty_LT.Value
              OUT_VaMTQR_M_MtrAMaxCpblty_LT_Value: accessed-variable=VaMTQR_M_MtrAMaxCpblty_LT.Value
              OUT_VaMTQR_M_MtrAMinCpblty_LT_Value: accessed-variable=VaMTQR_M_MtrAMinCpblty_LT.Value
              OUT_VaMTQR_n_MtrACpbltyspd_Value: accessed-variable=VaMTQR_n_MtrACpbltyspd.Value
              OUT_VaMTQR_n_MtrCCpbltyspd_Value: accessed-variable=VaMTQR_n_MtrCCpbltyspd.Value
              OUT_VeMTQR_M_TaMin_Value: accessed-variable=VeMTQR_M_TaMin.Value
              OUT_VeMTQR_M_TaMax_Value: accessed-variable=VeMTQR_M_TaMax.Value
              OUT_VeMTQR_M_TbMin_Value: accessed-variable=VeMTQR_M_TbMin.Value
              OUT_VeMTQR_M_TbMax_Value: accessed-variable=VeMTQR_M_TbMax.Value
              OUT_VeMTQR_M_TcMin_Value: accessed-variable=VeMTQR_M_TcMin.Value
              OUT_VeMTQR_M_TcMax_Value: accessed-variable=VeMTQR_M_TcMax.Value
      variation point proxy Variant_HSCL_FEAD1: category=CONDITION, condition-access=0
